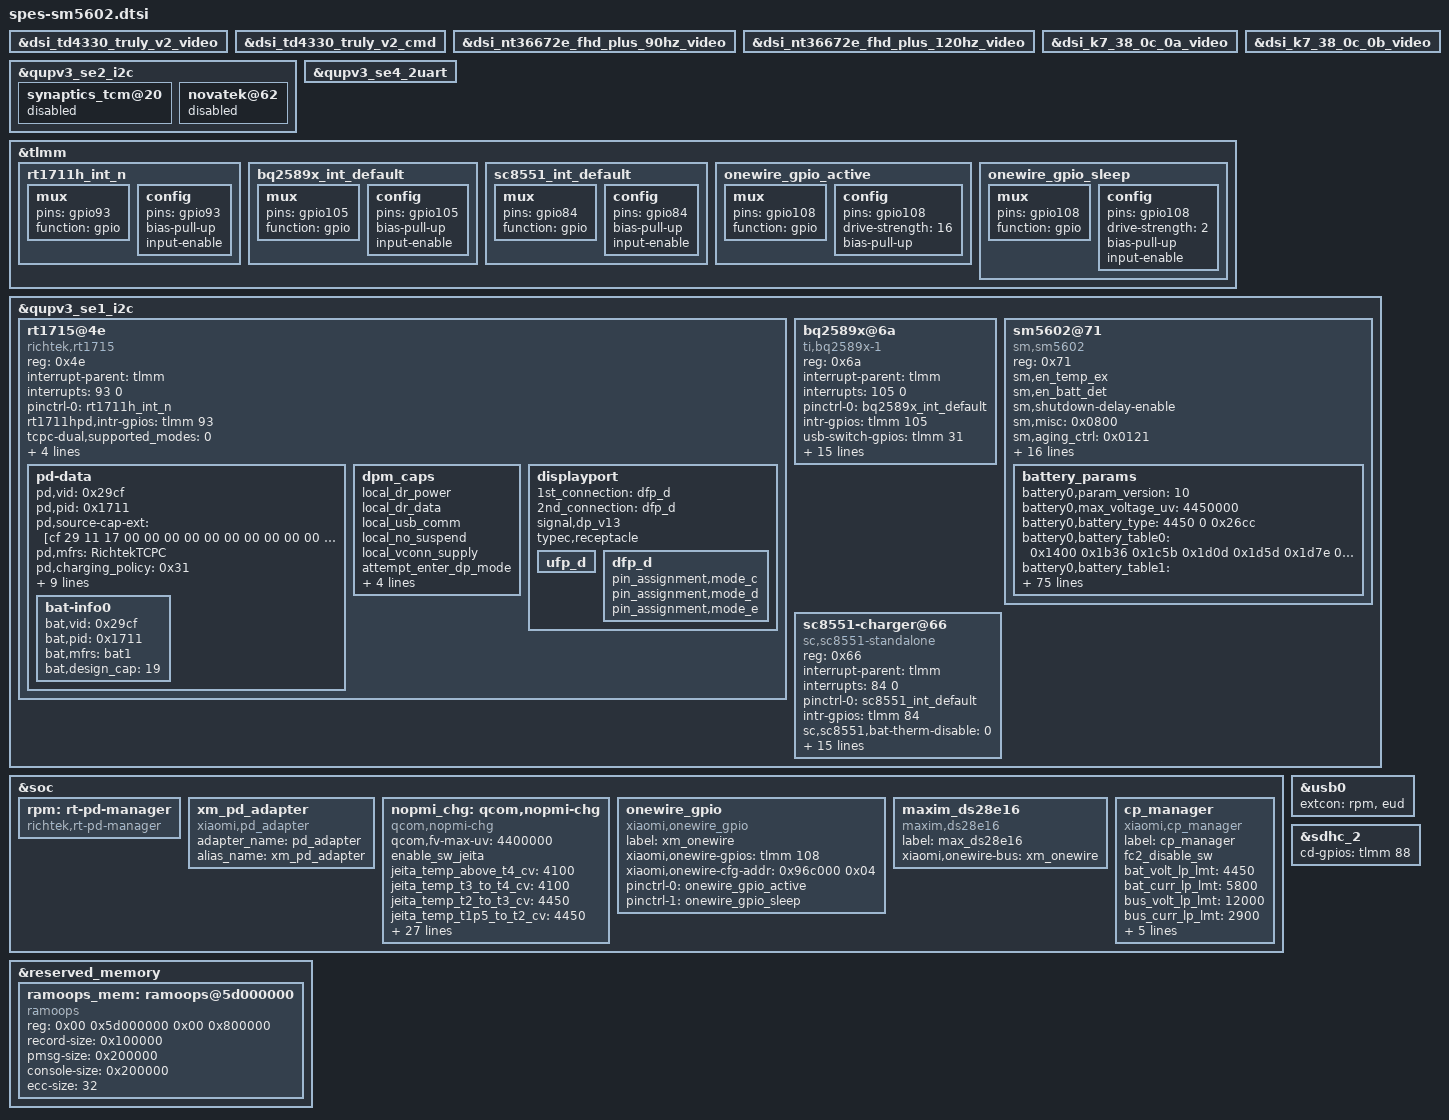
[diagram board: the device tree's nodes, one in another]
#include "khaje-idp.dtsi"

&dsi_td4330_truly_v2_video {
	/delete-property/ qcom,esd-check-enabled;
};

&dsi_td4330_truly_v2_cmd {
	/delete-property/ qcom,esd-check-enabled;
};

&dsi_nt36672e_fhd_plus_90hz_video {
	/delete-property/ qcom,esd-check-enabled;
};

&dsi_nt36672e_fhd_plus_120hz_video {
	/delete-property/ qcom,esd-check-enabled;
};

&dsi_k7_38_0c_0a_video {
	/delete-property/ qcom,esd-check-enabled;
};

&dsi_k7_38_0c_0b_video {
	/delete-property/ qcom,esd-check-enabled;
};

&qupv3_se2_i2c {
	synaptics_tcm@20 {
		status = "disabled";
	};

	novatek@62 {
		status = "disabled";
	};
};

&qupv3_se4_2uart {
	status = "ok";
};

&tlmm {
	/* RT1711H - TCPC */
	rt1711h_int_n: rt1711h_int_n {
		mux {
			pins = "gpio93";
			function = "gpio";
		};

		config {
			pins = "gpio93";
			bias-pull-up;
			input-enable;
		};
	};

	/* BQ-CHARGER */
	bq2589x_int_default: bq2589x_int_default {
		mux {
			pins = "gpio105";
			function = "gpio";
		};

		config {
			pins = "gpio105";
			bias-pull-up;
			input-enable;
		};
	};

	/* sc8551-charger */
	sc8551_int_default: sc8551_int_default {
		mux {
			pins = "gpio84";
			function = "gpio";
		};

		config {
			pins = "gpio84";
			bias-pull-up;
			input-enable;
		};
	};

	/* Onewire */
	onewire_gpio_active: onewire_gpio_active {
		mux {
			pins = "gpio108";
			function = "gpio";
		};

		config {
			pins = "gpio108";
			drive-strength = <16>;
			bias-pull-up;
		};
	};

	onewire_gpio_sleep: onewire_gpio_sleep {
		mux {
			pins = "gpio108";
			function = "gpio";
		};

		config {
			pins = "gpio108";
			drive-strength = <2>;
			bias-pull-up;
			input-enable;
		};
	};
};

&qupv3_se1_i2c {
	status = "ok";
	#address-cells = <1>;
	#size-cells = <0>;

	/* TCPC: Richtek RT1715 Type-C PD Controller */
	rt1715@4e {
		compatible = "richtek,rt1715";
		reg = <0x4e>;
		interrupt-parent = <&tlmm>;
		interrupts = <93 0>;
		pinctrl-names = "default";
		pinctrl-0 = <&rt1711h_int_n>;
		rt1711hpd,intr-gpios = <&tlmm 93 0>;
		tcpc-dual,supported_modes = <0>;
		rt-tcpc,name = "type_c_port0";
		/* 0: Unknown, 1: SNK, 2: SRC, 3: DRP, 4: Try.SRC, 5: Try.SNK */
		rt-tcpc,role_def = <5>;
		/* 0: Default, 1: 1.5A, 2: 3.0A */
		rt-tcpc,rp_level = <0>;
		/* 0: Never, 1: Always, 2: EMarkOnly, 3: StartOnly */
		rt-tcpc,vconn_supply = <1>;

		pd-data {
			pd,vid = <0x29cf>;
			pd,pid = <0x1711>;
			pd,source-cap-ext = [cf 29 11 17 00 00 00 00 00 00 00 00 00 00 00 00 00 00 00 00 00 00 00 02 00];
			pd,mfrs = "RichtekTCPC";
			/*
			 * VSAFE5V = 0x00, MAX_POWER = 0x01, CUSTOM = 0x02
			 * MAX_POWER_LV = 0x21, MAX_POWER_LVIC = 0x31
			 * MAX_POWER_HV = 0x41, MAX_POWER_HVIC = 0x51
			 */
			pd,charging_policy = <0x31>;

			/*
			 * Fixed 5V, 500 mA = <0x00019032>
			 * Fixed 5V, 1A = <0x00019064>
			 * Fixed 5V, 1.5A = <0x00019096>
			 * Fixed 5V, 2A = <0x000190c8>
			 * Fixed 5V, 3A = <0x0001912c>
			 * Fixed 9V, 500 mA = <0x0002d032>
			 * Fixed 9V, 1A = <0x0002d064>
			 * Fixed 9V, 2A = <0x0002d0c8>
			 * Fixed 9V, 3A = <0x0002d12c>
			 * Variable 5-9V, 1A = <0x8642d064>
			 * Variable 5-9V, 2A = <0x8642d0c8>
			 * Variable 5-9V, 3A = <0x8642d12c>
			 * PPS 3V ~ 5.9V, 3A = <0xC0761E3C>
			 * PPS 5V ~ 11.0V, 3A = <0xC0DC323C>
			 */
			pd,source-pdo-size = <1>;
			pd,source-pdo-data = <0x00019032>;
			pd,sink-pdo-size = <1>;
			pd,sink-pdo-data = <0x000190c8>;
			pd,id-vdo-size = <6>;
			pd,id-vdo-data = <0xd14029cf 0x0 0x17110000 0x61000000 0x0 0x41000000>;
			bat,nr = <1>;
			pd,country_nr = <0>;
			bat-info0 {
				bat,vid = <0x29cf>;
				bat,pid = <0x1711>;
				bat,mfrs = "bat1";
				bat,design_cap = <19>;
			};
		};

		dpm_caps {
			local_dr_power;
			local_dr_data;
			local_usb_comm;
			local_no_suspend;
			local_vconn_supply;
			attempt_enter_dp_mode;
			attempt_discover_cable;
			attempt_discover_id;
			pr_check = <0>;
			dr_check = <0>;
		};

		displayport {
			1st_connection = "dfp_d";
			2nd_connection = "dfp_d";
			signal,dp_v13;
			typec,receptacle;

			ufp_d {};

			dfp_d {
				pin_assignment,mode_c;
				pin_assignment,mode_d;
				pin_assignment,mode_e;
			};
		};
	};

	/* BQ charger */
	bq2589x@6a {
		compatible = "ti,bq2589x-1";
		reg = <0x6a>;
		interrupt-parent = <&tlmm>;
		interrupts = <105 0>;
		pinctrl-names = "default";
		pinctrl-0 = <&bq2589x_int_default>;
		intr-gpios = <&tlmm 105 0>;
		usb-switch-gpios = <&tlmm 31 0>;
		ti,bq2589x,vbus-volt-high-level = <8700>;
		ti,bq2589x,vbus-volt-low-level = <4400>;
		ti,bq2589x,vbat-min-volt-to-tuneup = <3000>;
		ti,bq2589x,charge-voltage = <4450>;
		ti,bq2589x,charge-current = <2000>;
		ti,bq2589x,charge-current-1500 = <1500>;
		ti,bq2589x,charge-current-1000 = <1000>;
		ti,bq2589x,charge-current-500 = <500>;
		ti,bq2589x,charge-current-3500 = <3500>;
		ti,bq2589x,input-current-2000 = <2000>;
		ti,bq2589x,term-current = <256>;
		ti,bq2589x,enable-auto-dpdm;
		ti,bq2589x,enable-termination;
		ti,bq2589x,enable-ico;
		ti,bq2589x,use-absolute-vindpm;
	};

	/* Fuel gauge */
	sm5602@71 {
		compatible = "sm,sm5602";
		reg = <0x71>;
		sm,en_temp_ex;
		sm,en_batt_det;
		sm,shutdown-delay-enable;
		sm,misc = <0x0800>;
		sm,aging_ctrl = <0x0121>;
		sm,cycle_cfg = <0x7000>;
		sm,fg_irq_set = <0x07ff>;
		sm,rsns = <0>;
		sm,battery_table_num = <0>;
		sm,param_version = <5>;
		sm,low_soc1 = <1>;
		sm,low_soc2 = <15>;
		sm,v_l_alarm = <3400>;
		sm,v_h_alarm = <4450>;
		sm,t_l_alarm_in = <54>;
		sm,t_h_alarm_in = <1>;
		sm,t_l_alarm_ex = <0xd632>;
		sm,t_h_alarm_ex = <0x955f>;
		sm,rtrace = <7300>;
		sm,soc_decimal_rate = <0 38 10 35 20 33 30 33 40 33 50 33 60 33 70 30 80 25 90 20 95 10>;

		battery_params {
			/* battery 0 */
			battery0,param_version = <10>;
			battery0,max_voltage_uv = <4450000>;
			battery0,battery_type = <4450 0 0x26cc>;
			battery0,battery_table0 = <0x1400 0x1b36 0x1c5b 0x1d0d 0x1d5d 0x1d7e 0x1d8d 0x1d97 0x1dc1 0x1df0 0x1e1a 0x1e4a 0x1e6a 0x1ea2 0x1eee 0x1f37 0x1fb9 0x2015 0x2079 0x20e8 0x219c 0x2257 0x2351 0x24cc>;
			battery0,battery_table1 = <0x00 0x66 0x1ea 0x36f 0x472 0x574 0x7fc 0xb04 0xe0d 0x1218 0x1727 0x1c35 0x2143 0x28d9 0x306e 0x357c 0x3a8b 0x3f99 0x44a7 0x49b5 0x514b 0x58e0 0x6400 0x64e6>;
			battery0,battery_table2 = <0x1620 0x1113 0xf10 0xd0e 0xc0c 0xb0b 0xa0a 0xa0a>;
			battery0,alpha = <0xcc>;
			battery0,beta = <0x25>;
			battery0,rs = <0x5f>;
			battery0,rs_value = <0x50 0x10a 0x3800 0x48>;
			battery0,vit_period = <0x325a>;
			battery0,volt_cal = <0x8000>;
			battery0,mix_value = <3>;
			battery0,curr_offset = <0x00>;
			battery0,curr_slope = <0x8080>;
			battery0,topoff_soc = <7 300 100>;
			battery0,temp_std = <25>;
			battery0,temp_offset = <0 11 1 0 8 (-1)>;
			battery0,temp_cal = <0 6 1 11 (-1) 0 6 1 9 1>;
			battery0,ext_temp_cal = <0 2 1 2 1 1 2 3 2 3>;
			battery0,tempoff = <3400 100>;
			battery0,fcm_offset = <0x48>;
			battery0,thermal_table = <0x9d45 0x9cf7 0x9ca8 0x9c5a 0x9c0c 0x9bbe 0x9b70 0x9b21 0x9ad2 0x9a83 0x9a33 0x99e3 0x9992 0x9940 0x98ef 0x989d 0x984b 0x97f8 0x97a5 0x9752
				0x96fe 0x96aa 0x9656 0x9601 0x95ac 0x9556 0x9500 0x94aa 0x9454 0x93fd 0x93a6 0x934f 0x92f7 0x929f 0x9246 0x91ed 0x9194 0x913b 0x90e1 0x9087
				0x902d 0x8fd2 0x8f78 0x8f1c 0x8ec1 0x8e65 0x8e09 0x8dad 0x8d51 0x8cf4 0x8c97 0x8c3a 0x8bdd 0x8b7f 0x8b21 0x8ac3 0x8a65 0x8a06 0x89a8 0x8949
				0x88ea 0x888b 0x882c 0x87cc 0x876d 0x870d 0x86ad 0x864d 0x85ed 0x858d 0x852d 0x84d1 0x847c 0x842b 0x83db 0x8389 0x8332 0x82d3 0x8269 0x81f1
				0x8168 0x80aa 0x7fa2 0x7e62 0x7cfd 0x7b85 0x7a0e 0x78a9 0x7769 0x7662 0x75a5 0x751d 0x74a6 0x743d 0x73df 0x7388 0x7337 0x72e8 0x7297 0x7244
				0x71e9 0x718a 0x712b 0x70cd 0x706e 0x7010 0x6fb2 0x6f54 0x6ef6 0x6e98 0x6e3b 0x6dde 0x6d81 0x6d24 0x6cc7 0x6c6b 0x6c0e 0x6bb2 0x6b57 0x6afb
				0x6aa0 0x6a45 0x69ea 0x6990 0x6936 0x68dc 0x6882 0x6829 0x67cf 0x6777 0x671e 0x66c6 0x666e 0x6616 0x65bf 0x6567 0x6510 0x64ba 0x6464 0x640e
				0x63b8 0x6363 0x630e 0x62b9 0x6265 0x6211 0x61bd 0x6169 0x6116 0x60c3 0x6071 0x601f 0x5fcd 0x5f7b 0x5f2a 0x5ed9 0x5e89 0x5e39 0x5de9 0x5d99
				0x5d4a 0x5cfb 0x5cad 0x5c5f 0x5c11 0x5bc4 0x5b76 0x5b2a 0x5add 0x5a91 0x5a45 0x59f9 0x59ae 0x5963 0x5918 0x58ce 0x5884 0x583a 0x57f0 0x57a7
				0x575e 0x5715 0x56cd 0x5685 0x563d 0x55f6 0x55af 0x5568 0x5522 0x54db 0x5495 0x544f 0x540a 0x53c4 0x537f 0x533a 0x52f6 0x52b1 0x526d 0x5229
				0x51e5 0x51a1 0x515e 0x511a 0x50d7 0x5094 0x5052 0x500f 0x4fcc 0x4f8a 0x4f48 0x4f06 0x4ec4 0x4e83 0x4e41 0x4e00 0x4dbf 0x4d7e 0x4d3d 0x4cfc
				0x4cbb 0x4c7a 0x4c3a 0x4bf9 0x4bb8 0x4b78 0x4b38 0x4af7 0x4ab7 0x4a77 0x4a37 0x49f7 0x49b7 0x4977 0x4937 0x48f8 0x48b8 0x4879 0x4839 0x47f9
				0x47ba 0x477b 0x473b 0x46fc 0x46bd 0x467d 0x463e 0x45ff 0x45c0 0x4581 0x4542 0x4503 0x44c4 0x4485 0x4447 0x4408 0x43c9 0x438b 0x434c 0x430e
				0x42d0 0x4292 0x4254 0x4216 0x41d8 0x419a 0x415d 0x4120 0x40e2 0x40a6 0x4069 0x402d 0x3ff0 0x3fb4 0x3f79 0x3f3d 0x3f02 0x3ec6 0x3e8c 0x3e51
				0x3e17 0x3ddd 0x3da4 0x3d6a 0x3d31 0x3cf9 0x3cc0 0x3c88 0x3c50 0x3c18 0x3be1 0x3baa 0x3b73 0x3b3d 0x3b06 0x3ad1 0x3a9b 0x3a65 0x3a30 0x39fb
				0x39c6 0x3991 0x395d 0x3928 0x38f4 0x38c0 0x388c 0x3859 0x3826 0x37f3 0x37c0 0x378e 0x375b 0x3729 0x36f8 0x36c6 0x3695 0x3664 0x3634 0x3603
				0x35d3 0x35a3 0x3574 0x3544 0x3515 0x34e7 0x34b8 0x348a 0x345c 0x342e 0x3400 0x33d3 0x33a5 0x3378 0x334b 0x331f 0x32f2 0x32c6 0x329a 0x326e
				0x3242 0x3216 0x31ea 0x31bf 0x3193 0x3167 0x313c 0x3111 0x30e6 0x30bc 0x3092 0x3068 0x303f 0x3016 0x2fed 0x2fc5 0x2f9c 0x2f74 0x2f4c 0x2f25
				0x2efd 0x2ed6 0x2eaf 0x2e88 0x2e61 0x2e3b 0x2e14 0x2dee 0x2dc8 0x2da2 0x2d7c 0x2d56 0x2d30 0x2d0a 0x2ce5 0x2cbf 0x2c99 0x2c74 0x2c4f 0x2c2a
				0x2c06 0x2be2 0x2bbe 0x2b9a 0x2b77 0x2b54 0x2b31 0x2b0e 0x2aeb 0x2ac9 0x2aa6 0x2a83 0x2a61 0x2a3f 0x2a1c 0x29fa 0x29d9 0x29b7 0x2995 0x2974
				0x2953 0x2932 0x2912 0x28f2 0x28d2 0x28b2 0x2892 0x2872 0x2853 0x2833 0x2814 0x27f5 0x27d5 0x27b6 0x2796 0x2777 0x2758 0x2739 0x271a 0x26fc
				0x26de 0x26c0 0x26a3 0x2686 0x2669 0x264c 0x2630 0x2613 0x25f7 0x25da 0x25be 0x25a2 0x2585 0x2569 0x254c 0x2530 0x2514 0x24f8 0x24dc 0x24c0
				0x24a5 0x248a 0x246f 0x2454 0x2439 0x241f 0x2404 0x23ea 0x23d0 0x23b6 0x239c 0x2382 0x2369 0x234f 0x2336 0x231d 0x2304 0x22eb 0x22d2 0x22ba
				0x22a1 0x2289 0x2270 0x2258 0x2240 0x2228 0x2210 0x21f8 0x21e0 0x21c9 0x21b1 0x219a 0x2182 0x216b 0x2154 0x213c 0x2125 0x210f 0x20f8 0x20e1
				0x20cb 0x20b5 0x209f 0x2089 0x2073 0x205e 0x2048 0x2033 0x201d 0x2008 0x1ff3 0x1fde 0x1fc9 0x1fb4 0x1f9f 0x1f8a 0x1f75 0x1f61 0x1f4c 0x1f38
				0x1f23 0x1f0f 0x1efa 0x1ee6 0x1ed1 0x1ebd 0x1ea9 0x1e95 0x1e81 0x1e6d 0x1e59 0x1e45 0x1e32 0x1e1f 0x1e0b 0x1df8 0x1de5 0x1dd2 0x1dbf 0x1dad
				0x1d9a 0x1d88 0x1d75 0x1d63 0x1d51 0x1d3f 0x1d2e 0x1d1c 0x1d0a 0x1cf9 0x1ce7 0x1cd5 0x1cc4 0x1cb3 0x1ca1 0x1c90 0x1c7f 0x1c6e 0x1c5d 0x1c4c
				0x1c3b 0x1c2a 0x1c19 0x1c09 0x1bf8 0x1be7 0x1bd7 0x1bc6 0x1bb6 0x1ba5 0x1b95 0x1b85 0x1b75 0x1b65 0x1b55 0x1b45 0x1b35 0x1b25 0x1b16 0x1b06
				0x1af7 0x1ae8 0x1ad9 0x1ac9 0x1abb 0x1aac 0x1a9d 0x1a8e 0x1a7f 0x1a71 0x1a62 0x1a53 0x1a45 0x1a36 0x1a28 0x1a19 0x1a0b 0x19fc 0x19ee 0x19e0
				0x19d2 0x19c4 0x19b6 0x19a9 0x199b 0x198e 0x1980 0x1973 0x1965 0x1958 0x194b 0x193e 0x1931 0x1924 0x1917 0x190a 0x18fe 0x18f1 0x18e4 0x18d8
				0x18cb 0x18be 0x18b2 0x18a5 0x1899 0x188c 0x187f 0x1873 0x1867 0x185a 0x184e 0x1842 0x1836 0x1829 0x181d 0x1811 0x1805 0x17f9 0x17ed 0x17e2
				0x17d6 0x17ca 0x17bf 0x17b3 0x17a8 0x179d 0x1791 0x1786 0x177b 0x1770 0x1765 0x175a 0x174f 0x1744 0x173a 0x172f 0x1724 0x171a 0x170f 0x1705
				0x16fa 0x16f0 0x16e5 0x16db 0x16d0 0x16c6 0x16bc 0x16b1 0x16a7 0x169d 0x1693 0x1689 0x167f 0x1675 0x166b 0x1661 0x1658 0x164e 0x1644 0x163b
				0x1631 0x1627 0x161e 0x1614 0x160b 0x1601 0x15f8 0x15ef 0x15e5 0x15dc 0x15d3 0x15ca 0x15c1 0x15b8 0x15af 0x15a5 0x159d 0x1594 0x158b 0x1582
				0x1579 0x1570 0x1568 0x155f 0x1556 0x154e 0x1545 0x153d 0x1534 0x152c 0x1523 0x151a 0x1512 0x1509 0x1501 0x14f8 0x14f0 0x14e8 0x14df 0x14d7
				0x14cf 0x14c7 0x14bf 0x14b7 0x14af 0x14a8 0x14a0 0x1498 0x1490 0x1489 0x1481 0x1479 0x1472 0x146a 0x1462 0x145b 0x1453 0x144c 0x1444 0x143c
				0x1435 0x142e 0x1426 0x141f 0x1417 0x1410 0x1409 0x1402 0x13fa 0x13f3 0x13ec 0x13e5 0x13de 0x13d7 0x13d0 0x13c9 0x13c2 0x13bb 0x13b4 0x13ad
				0x13a6 0x139f 0x1399 0x1392 0x138b 0x1385 0x137e 0x1377 0x1371 0x136a 0x1364 0x135e 0x1357 0x1351 0x134a 0x1344 0x133e 0x1338 0x1331 0x132b
				0x1325 0x131f 0x1319 0x1313 0x130d 0x1307 0x1301 0x12fb 0x12f6 0x12f0 0x12ea 0x12e4 0x12de 0x12d9 0x12d3 0x12cd 0x12c7 0x12c2 0x12bc 0x12b7
				0x12b1 0x12ab 0x12a6 0x12a1 0x129b 0x1296 0x1290 0x128b 0x1286 0x1280 0x127b 0x1276 0x1270 0x126b 0x1265 0x1260 0x125a 0x1255 0x1250 0x124a
				0x1245 0x1240 0x123b 0x1235 0x1230 0x122b 0x1226 0x1221 0x121c 0x1217 0x1212 0x120d 0x1208 0x1203 0x11fe 0x11f9 0x11f4 0x11ef 0x11eb 0x11e6
				0x11e1 0x11dc 0x11d7 0x11d3 0x11ce 0x11c9 0x11c5 0x11c0 0x11bb 0x11b7 0x11b2 0x11ad 0x11a9 0x11a4 0x11a0 0x119b 0x1197 0x1192 0x118e 0x1189
				0x1185 0x1181 0x117c 0x1178 0x1174 0x116f 0x116b 0x1167 0x1162 0x115e 0x115a 0x1156 0x1152 0x114e 0x114a 0x1146 0x1142 0x113e 0x113a 0x1136
				0x1132 0x112e 0x112a 0x1126 0x1122 0x111e 0x111a 0x1117 0x1113 0x110f 0x110b 0x1107 0x1103 0x1100 0x10fc 0x10f8 0x10f5 0x10f1 0x10ed 0x10ea
				0x10e6 0x10e2 0x10df 0x10db 0x10d7 0x10d4 0x10d0 0x10cd 0x10c9 0x10c6 0x10c2 0x10bf 0x10bb 0x10b8 0x10b4 0x10b1 0x10ae 0x10aa 0x10a7 0x10a3
				0x10a0 0x109d 0x1099 0x1096 0x1092 0x108f 0x108b 0x1088 0x1085 0x1081 0x107e 0x107b 0x1077 0x1074 0x1071 0x106e 0x106b 0x1067 0x1064 0x1061
				0x105e 0x105b 0x1058 0x1055 0x1052 0x104f 0x104c 0x1049 0x1046 0x1043 0x1040 0x103d 0x103a 0x1037 0x1034 0x1031 0x102e 0x102b 0x1028 0x1025
				0x1022 0x101f 0x101c 0x1019 0x1017 0x1014 0x1011 0x100e 0x100c 0x1009 0x1006 0x1003 0x1000 0x0ffe 0x0ffb 0x0ff8 0x0ff5 0x0ff2 0x0fef 0x0fed
				0x0fea 0x0fe7 0x0fe5 0x0fe2 0x0fdf 0x0fdd 0x0fda 0x0fd8 0x0fd5 0x0fd3 0x0fd0 0x0fcd 0x0fcb 0x0fc8 0x0fc6 0x0fc3 0x0fc1 0x0fbe 0x0fbc 0x0fb9
				0x0fb7 0x0fb5 0x0fb2 0x0fb0 0x0fae 0x0fab 0x0fa9 0x0fa7 0x0fa5 0x0fa2 0x0fa0 0x0f9e 0x0f9c 0x0f99 0x0f97 0x0f95 0x0f93 0x0f91 0x0f8e 0x0f8c 0x0f8a>;
			/* battery 1 */
			battery1,param_version = <10>;
			battery1,max_voltage_uv = <4450000>;
			battery1,battery_type = <4450 0 0x26cc>;
			battery1,battery_table0 = <0x1400 0x1b36 0x1c5b 0x1d0d 0x1d5d 0x1d7e 0x1d8d 0x1d97 0x1dc1 0x1df0 0x1e1a 0x1e4a 0x1e6a 0x1ea2 0x1eee 0x1f37 0x1fb9 0x2015 0x2079 0x20e8 0x219c 0x2257 0x2351 0x24cc>;
			battery1,battery_table1 = <0x00 0x66 0x1ea 0x36f 0x472 0x574 0x7fc 0xb04 0xe0d 0x1218 0x1727 0x1c35 0x2143 0x28d9 0x306e 0x357c 0x3a8b 0x3f99 0x44a7 0x49b5 0x514b 0x58e0 0x6400 0x64e6>;
			battery1,battery_table2 = <0x1620 0x1113 0xf10 0xd0e 0xc0c 0xb0b 0xa0a 0xa0a>;
			battery1,alpha = <0xcc>;
			battery1,beta = <0x25>;
			battery1,rs = <0x5f>;
			battery1,rs_value = <0x50 0x10a 0x3800 0x48>;
			battery1,vit_period = <0x325a>;
			battery1,volt_cal = <0x8000>;
			battery1,mix_value = <3>;
			battery1,curr_offset = <0x00>;
			battery1,curr_slope = <0x8080>;
			battery1,topoff_soc = <7 300 100>;
			battery1,temp_std = <25>;
			battery1,temp_offset = <0 11 1 0 8 (-1)>;
			battery1,temp_cal = <0 6 1 11 (-1) 0 6 1 9 1>;
			battery1,ext_temp_cal = <0 2 1 2 1 1 2 3 2 3>;
			battery1,tempoff = <3400 100>;
			battery1,fcm_offset = <0x48>;
			battery1,thermal_table = <0x9d45 0x9cf7 0x9ca8 0x9c5a 0x9c0c 0x9bbe 0x9b70 0x9b21 0x9ad2 0x9a83 0x9a33 0x99e3 0x9992 0x9940 0x98ef 0x989d 0x984b 0x97f8 0x97a5 0x9752
				0x96fe 0x96aa 0x9656 0x9601 0x95ac 0x9556 0x9500 0x94aa 0x9454 0x93fd 0x93a6 0x934f 0x92f7 0x929f 0x9246 0x91ed 0x9194 0x913b 0x90e1 0x9087
				0x902d 0x8fd2 0x8f78 0x8f1c 0x8ec1 0x8e65 0x8e09 0x8dad 0x8d51 0x8cf4 0x8c97 0x8c3a 0x8bdd 0x8b7f 0x8b21 0x8ac3 0x8a65 0x8a06 0x89a8 0x8949
				0x88ea 0x888b 0x882c 0x87cc 0x876d 0x870d 0x86ad 0x864d 0x85ed 0x858d 0x852d 0x84d1 0x847c 0x842b 0x83db 0x8389 0x8332 0x82d3 0x8269 0x81f1
				0x8168 0x80aa 0x7fa2 0x7e62 0x7cfd 0x7b85 0x7a0e 0x78a9 0x7769 0x7662 0x75a5 0x751d 0x74a6 0x743d 0x73df 0x7388 0x7337 0x72e8 0x7297 0x7244
				0x71e9 0x718a 0x712b 0x70cd 0x706e 0x7010 0x6fb2 0x6f54 0x6ef6 0x6e98 0x6e3b 0x6dde 0x6d81 0x6d24 0x6cc7 0x6c6b 0x6c0e 0x6bb2 0x6b57 0x6afb
				0x6aa0 0x6a45 0x69ea 0x6990 0x6936 0x68dc 0x6882 0x6829 0x67cf 0x6777 0x671e 0x66c6 0x666e 0x6616 0x65bf 0x6567 0x6510 0x64ba 0x6464 0x640e
				0x63b8 0x6363 0x630e 0x62b9 0x6265 0x6211 0x61bd 0x6169 0x6116 0x60c3 0x6071 0x601f 0x5fcd 0x5f7b 0x5f2a 0x5ed9 0x5e89 0x5e39 0x5de9 0x5d99
				0x5d4a 0x5cfb 0x5cad 0x5c5f 0x5c11 0x5bc4 0x5b76 0x5b2a 0x5add 0x5a91 0x5a45 0x59f9 0x59ae 0x5963 0x5918 0x58ce 0x5884 0x583a 0x57f0 0x57a7
				0x575e 0x5715 0x56cd 0x5685 0x563d 0x55f6 0x55af 0x5568 0x5522 0x54db 0x5495 0x544f 0x540a 0x53c4 0x537f 0x533a 0x52f6 0x52b1 0x526d 0x5229
				0x51e5 0x51a1 0x515e 0x511a 0x50d7 0x5094 0x5052 0x500f 0x4fcc 0x4f8a 0x4f48 0x4f06 0x4ec4 0x4e83 0x4e41 0x4e00 0x4dbf 0x4d7e 0x4d3d 0x4cfc
				0x4cbb 0x4c7a 0x4c3a 0x4bf9 0x4bb8 0x4b78 0x4b38 0x4af7 0x4ab7 0x4a77 0x4a37 0x49f7 0x49b7 0x4977 0x4937 0x48f8 0x48b8 0x4879 0x4839 0x47f9
				0x47ba 0x477b 0x473b 0x46fc 0x46bd 0x467d 0x463e 0x45ff 0x45c0 0x4581 0x4542 0x4503 0x44c4 0x4485 0x4447 0x4408 0x43c9 0x438b 0x434c 0x430e
				0x42d0 0x4292 0x4254 0x4216 0x41d8 0x419a 0x415d 0x4120 0x40e2 0x40a6 0x4069 0x402d 0x3ff0 0x3fb4 0x3f79 0x3f3d 0x3f02 0x3ec6 0x3e8c 0x3e51
				0x3e17 0x3ddd 0x3da4 0x3d6a 0x3d31 0x3cf9 0x3cc0 0x3c88 0x3c50 0x3c18 0x3be1 0x3baa 0x3b73 0x3b3d 0x3b06 0x3ad1 0x3a9b 0x3a65 0x3a30 0x39fb
				0x39c6 0x3991 0x395d 0x3928 0x38f4 0x38c0 0x388c 0x3859 0x3826 0x37f3 0x37c0 0x378e 0x375b 0x3729 0x36f8 0x36c6 0x3695 0x3664 0x3634 0x3603
				0x35d3 0x35a3 0x3574 0x3544 0x3515 0x34e7 0x34b8 0x348a 0x345c 0x342e 0x3400 0x33d3 0x33a5 0x3378 0x334b 0x331f 0x32f2 0x32c6 0x329a 0x326e
				0x3242 0x3216 0x31ea 0x31bf 0x3193 0x3167 0x313c 0x3111 0x30e6 0x30bc 0x3092 0x3068 0x303f 0x3016 0x2fed 0x2fc5 0x2f9c 0x2f74 0x2f4c 0x2f25
				0x2efd 0x2ed6 0x2eaf 0x2e88 0x2e61 0x2e3b 0x2e14 0x2dee 0x2dc8 0x2da2 0x2d7c 0x2d56 0x2d30 0x2d0a 0x2ce5 0x2cbf 0x2c99 0x2c74 0x2c4f 0x2c2a
				0x2c06 0x2be2 0x2bbe 0x2b9a 0x2b77 0x2b54 0x2b31 0x2b0e 0x2aeb 0x2ac9 0x2aa6 0x2a83 0x2a61 0x2a3f 0x2a1c 0x29fa 0x29d9 0x29b7 0x2995 0x2974
				0x2953 0x2932 0x2912 0x28f2 0x28d2 0x28b2 0x2892 0x2872 0x2853 0x2833 0x2814 0x27f5 0x27d5 0x27b6 0x2796 0x2777 0x2758 0x2739 0x271a 0x26fc
				0x26de 0x26c0 0x26a3 0x2686 0x2669 0x264c 0x2630 0x2613 0x25f7 0x25da 0x25be 0x25a2 0x2585 0x2569 0x254c 0x2530 0x2514 0x24f8 0x24dc 0x24c0
				0x24a5 0x248a 0x246f 0x2454 0x2439 0x241f 0x2404 0x23ea 0x23d0 0x23b6 0x239c 0x2382 0x2369 0x234f 0x2336 0x231d 0x2304 0x22eb 0x22d2 0x22ba
				0x22a1 0x2289 0x2270 0x2258 0x2240 0x2228 0x2210 0x21f8 0x21e0 0x21c9 0x21b1 0x219a 0x2182 0x216b 0x2154 0x213c 0x2125 0x210f 0x20f8 0x20e1
				0x20cb 0x20b5 0x209f 0x2089 0x2073 0x205e 0x2048 0x2033 0x201d 0x2008 0x1ff3 0x1fde 0x1fc9 0x1fb4 0x1f9f 0x1f8a 0x1f75 0x1f61 0x1f4c 0x1f38
				0x1f23 0x1f0f 0x1efa 0x1ee6 0x1ed1 0x1ebd 0x1ea9 0x1e95 0x1e81 0x1e6d 0x1e59 0x1e45 0x1e32 0x1e1f 0x1e0b 0x1df8 0x1de5 0x1dd2 0x1dbf 0x1dad
				0x1d9a 0x1d88 0x1d75 0x1d63 0x1d51 0x1d3f 0x1d2e 0x1d1c 0x1d0a 0x1cf9 0x1ce7 0x1cd5 0x1cc4 0x1cb3 0x1ca1 0x1c90 0x1c7f 0x1c6e 0x1c5d 0x1c4c
				0x1c3b 0x1c2a 0x1c19 0x1c09 0x1bf8 0x1be7 0x1bd7 0x1bc6 0x1bb6 0x1ba5 0x1b95 0x1b85 0x1b75 0x1b65 0x1b55 0x1b45 0x1b35 0x1b25 0x1b16 0x1b06
				0x1af7 0x1ae8 0x1ad9 0x1ac9 0x1abb 0x1aac 0x1a9d 0x1a8e 0x1a7f 0x1a71 0x1a62 0x1a53 0x1a45 0x1a36 0x1a28 0x1a19 0x1a0b 0x19fc 0x19ee 0x19e0
				0x19d2 0x19c4 0x19b6 0x19a9 0x199b 0x198e 0x1980 0x1973 0x1965 0x1958 0x194b 0x193e 0x1931 0x1924 0x1917 0x190a 0x18fe 0x18f1 0x18e4 0x18d8
				0x18cb 0x18be 0x18b2 0x18a5 0x1899 0x188c 0x187f 0x1873 0x1867 0x185a 0x184e 0x1842 0x1836 0x1829 0x181d 0x1811 0x1805 0x17f9 0x17ed 0x17e2
				0x17d6 0x17ca 0x17bf 0x17b3 0x17a8 0x179d 0x1791 0x1786 0x177b 0x1770 0x1765 0x175a 0x174f 0x1744 0x173a 0x172f 0x1724 0x171a 0x170f 0x1705
				0x16fa 0x16f0 0x16e5 0x16db 0x16d0 0x16c6 0x16bc 0x16b1 0x16a7 0x169d 0x1693 0x1689 0x167f 0x1675 0x166b 0x1661 0x1658 0x164e 0x1644 0x163b
				0x1631 0x1627 0x161e 0x1614 0x160b 0x1601 0x15f8 0x15ef 0x15e5 0x15dc 0x15d3 0x15ca 0x15c1 0x15b8 0x15af 0x15a5 0x159d 0x1594 0x158b 0x1582
				0x1579 0x1570 0x1568 0x155f 0x1556 0x154e 0x1545 0x153d 0x1534 0x152c 0x1523 0x151a 0x1512 0x1509 0x1501 0x14f8 0x14f0 0x14e8 0x14df 0x14d7
				0x14cf 0x14c7 0x14bf 0x14b7 0x14af 0x14a8 0x14a0 0x1498 0x1490 0x1489 0x1481 0x1479 0x1472 0x146a 0x1462 0x145b 0x1453 0x144c 0x1444 0x143c
				0x1435 0x142e 0x1426 0x141f 0x1417 0x1410 0x1409 0x1402 0x13fa 0x13f3 0x13ec 0x13e5 0x13de 0x13d7 0x13d0 0x13c9 0x13c2 0x13bb 0x13b4 0x13ad
				0x13a6 0x139f 0x1399 0x1392 0x138b 0x1385 0x137e 0x1377 0x1371 0x136a 0x1364 0x135e 0x1357 0x1351 0x134a 0x1344 0x133e 0x1338 0x1331 0x132b
				0x1325 0x131f 0x1319 0x1313 0x130d 0x1307 0x1301 0x12fb 0x12f6 0x12f0 0x12ea 0x12e4 0x12de 0x12d9 0x12d3 0x12cd 0x12c7 0x12c2 0x12bc 0x12b7
				0x12b1 0x12ab 0x12a6 0x12a1 0x129b 0x1296 0x1290 0x128b 0x1286 0x1280 0x127b 0x1276 0x1270 0x126b 0x1265 0x1260 0x125a 0x1255 0x1250 0x124a
				0x1245 0x1240 0x123b 0x1235 0x1230 0x122b 0x1226 0x1221 0x121c 0x1217 0x1212 0x120d 0x1208 0x1203 0x11fe 0x11f9 0x11f4 0x11ef 0x11eb 0x11e6
				0x11e1 0x11dc 0x11d7 0x11d3 0x11ce 0x11c9 0x11c5 0x11c0 0x11bb 0x11b7 0x11b2 0x11ad 0x11a9 0x11a4 0x11a0 0x119b 0x1197 0x1192 0x118e 0x1189
				0x1185 0x1181 0x117c 0x1178 0x1174 0x116f 0x116b 0x1167 0x1162 0x115e 0x115a 0x1156 0x1152 0x114e 0x114a 0x1146 0x1142 0x113e 0x113a 0x1136
				0x1132 0x112e 0x112a 0x1126 0x1122 0x111e 0x111a 0x1117 0x1113 0x110f 0x110b 0x1107 0x1103 0x1100 0x10fc 0x10f8 0x10f5 0x10f1 0x10ed 0x10ea
				0x10e6 0x10e2 0x10df 0x10db 0x10d7 0x10d4 0x10d0 0x10cd 0x10c9 0x10c6 0x10c2 0x10bf 0x10bb 0x10b8 0x10b4 0x10b1 0x10ae 0x10aa 0x10a7 0x10a3
				0x10a0 0x109d 0x1099 0x1096 0x1092 0x108f 0x108b 0x1088 0x1085 0x1081 0x107e 0x107b 0x1077 0x1074 0x1071 0x106e 0x106b 0x1067 0x1064 0x1061
				0x105e 0x105b 0x1058 0x1055 0x1052 0x104f 0x104c 0x1049 0x1046 0x1043 0x1040 0x103d 0x103a 0x1037 0x1034 0x1031 0x102e 0x102b 0x1028 0x1025
				0x1022 0x101f 0x101c 0x1019 0x1017 0x1014 0x1011 0x100e 0x100c 0x1009 0x1006 0x1003 0x1000 0x0ffe 0x0ffb 0x0ff8 0x0ff5 0x0ff2 0x0fef 0x0fed
				0x0fea 0x0fe7 0x0fe5 0x0fe2 0x0fdf 0x0fdd 0x0fda 0x0fd8 0x0fd5 0x0fd3 0x0fd0 0x0fcd 0x0fcb 0x0fc8 0x0fc6 0x0fc3 0x0fc1 0x0fbe 0x0fbc 0x0fb9
				0x0fb7 0x0fb5 0x0fb2 0x0fb0 0x0fae 0x0fab 0x0fa9 0x0fa7 0x0fa5 0x0fa2 0x0fa0 0x0f9e 0x0f9c 0x0f99 0x0f97 0x0f95 0x0f93 0x0f91 0x0f8e 0x0f8c 0x0f8a>;
			/* battery 2 */
			battery2,param_version = <10>;
			battery2,max_voltage_uv = <4450000>;
			battery2,battery_type = <4450 0 0x2699>;
			battery2,battery_table0 = <0x1400 0x1b48 0x1c6f 0x1cee 0x1d4a 0x1d7d 0x1d8d 0x1d9b 0x1dcd 0x1e03 0x1e2e 0x1e5c 0x1e7b 0x1e9f 0x1ee9 0x1f2f 0x1fb6 0x2010 0x2073 0x20e1 0x2194 0x2254 0x2351 0x24cc>;
			battery2,battery_table1 = <0x00 0x65 0x1ed 0x2f3 0x3f8 0x4fe 0x709 0xb1f 0xeb2 0x13ce 0x18e9 0x1e05 0x2321 0x283c 0x2fe6 0x3501 0x3a1d 0x3f39 0x4454 0x4970 0x5119 0x58c3 0x6400 0x64e6>;
			battery2,battery_table2 = <0x1620 0x1113 0xf10 0xd0e 0xc0c 0xb0b 0xa0a 0xa0a>;
			battery2,alpha = <0xcc>;
			battery2,beta = <0x25>;
			battery2,rs = <0x5f>;
			battery2,rs_value = <0x50 0x10a 0x3800 0x48>;
			battery2,vit_period = <0x325a>;
			battery2,volt_cal = <0x8000>;
			battery2,mix_value = <3>;
			battery2,curr_offset = <0x00>;
			battery2,curr_slope = <0x8080>;
			battery2,topoff_soc = <7 300 100>;
			battery2,temp_std = <25>;
			battery2,temp_offset = <0 11 1 0 8 (-1)>;
			battery2,temp_cal = <0 6 1 11 (-1) 0 6 1 9 1>;
			battery2,ext_temp_cal = <0 2 1 2 1 1 2 3 2 3>;
			battery2,tempoff = <3400 100>;
			battery2,fcm_offset = <0x48>;
			battery2,thermal_table = <0x9d45 0x9cf7 0x9ca8 0x9c5a 0x9c0c 0x9bbe 0x9b70 0x9b21 0x9ad2 0x9a83 0x9a33 0x99e3 0x9992 0x9940 0x98ef 0x989d 0x984b 0x97f8 0x97a5 0x9752
				0x96fe 0x96aa 0x9656 0x9601 0x95ac 0x9556 0x9500 0x94aa 0x9454 0x93fd 0x93a6 0x934f 0x92f7 0x929f 0x9246 0x91ed 0x9194 0x913b 0x90e1 0x9087
				0x902d 0x8fd2 0x8f78 0x8f1c 0x8ec1 0x8e65 0x8e09 0x8dad 0x8d51 0x8cf4 0x8c97 0x8c3a 0x8bdd 0x8b7f 0x8b21 0x8ac3 0x8a65 0x8a06 0x89a8 0x8949
				0x88ea 0x888b 0x882c 0x87cc 0x876d 0x870d 0x86ad 0x864d 0x85ed 0x858d 0x852d 0x84d1 0x847c 0x842b 0x83db 0x8389 0x8332 0x82d3 0x8269 0x81f1
				0x8168 0x80aa 0x7fa2 0x7e62 0x7cfd 0x7b85 0x7a0e 0x78a9 0x7769 0x7662 0x75a5 0x751d 0x74a6 0x743d 0x73df 0x7388 0x7337 0x72e8 0x7297 0x7244
				0x71e9 0x718a 0x712b 0x70cd 0x706e 0x7010 0x6fb2 0x6f54 0x6ef6 0x6e98 0x6e3b 0x6dde 0x6d81 0x6d24 0x6cc7 0x6c6b 0x6c0e 0x6bb2 0x6b57 0x6afb
				0x6aa0 0x6a45 0x69ea 0x6990 0x6936 0x68dc 0x6882 0x6829 0x67cf 0x6777 0x671e 0x66c6 0x666e 0x6616 0x65bf 0x6567 0x6510 0x64ba 0x6464 0x640e
				0x63b8 0x6363 0x630e 0x62b9 0x6265 0x6211 0x61bd 0x6169 0x6116 0x60c3 0x6071 0x601f 0x5fcd 0x5f7b 0x5f2a 0x5ed9 0x5e89 0x5e39 0x5de9 0x5d99
				0x5d4a 0x5cfb 0x5cad 0x5c5f 0x5c11 0x5bc4 0x5b76 0x5b2a 0x5add 0x5a91 0x5a45 0x59f9 0x59ae 0x5963 0x5918 0x58ce 0x5884 0x583a 0x57f0 0x57a7
				0x575e 0x5715 0x56cd 0x5685 0x563d 0x55f6 0x55af 0x5568 0x5522 0x54db 0x5495 0x544f 0x540a 0x53c4 0x537f 0x533a 0x52f6 0x52b1 0x526d 0x5229
				0x51e5 0x51a1 0x515e 0x511a 0x50d7 0x5094 0x5052 0x500f 0x4fcc 0x4f8a 0x4f48 0x4f06 0x4ec4 0x4e83 0x4e41 0x4e00 0x4dbf 0x4d7e 0x4d3d 0x4cfc
				0x4cbb 0x4c7a 0x4c3a 0x4bf9 0x4bb8 0x4b78 0x4b38 0x4af7 0x4ab7 0x4a77 0x4a37 0x49f7 0x49b7 0x4977 0x4937 0x48f8 0x48b8 0x4879 0x4839 0x47f9
				0x47ba 0x477b 0x473b 0x46fc 0x46bd 0x467d 0x463e 0x45ff 0x45c0 0x4581 0x4542 0x4503 0x44c4 0x4485 0x4447 0x4408 0x43c9 0x438b 0x434c 0x430e
				0x42d0 0x4292 0x4254 0x4216 0x41d8 0x419a 0x415d 0x4120 0x40e2 0x40a6 0x4069 0x402d 0x3ff0 0x3fb4 0x3f79 0x3f3d 0x3f02 0x3ec6 0x3e8c 0x3e51
				0x3e17 0x3ddd 0x3da4 0x3d6a 0x3d31 0x3cf9 0x3cc0 0x3c88 0x3c50 0x3c18 0x3be1 0x3baa 0x3b73 0x3b3d 0x3b06 0x3ad1 0x3a9b 0x3a65 0x3a30 0x39fb
				0x39c6 0x3991 0x395d 0x3928 0x38f4 0x38c0 0x388c 0x3859 0x3826 0x37f3 0x37c0 0x378e 0x375b 0x3729 0x36f8 0x36c6 0x3695 0x3664 0x3634 0x3603
				0x35d3 0x35a3 0x3574 0x3544 0x3515 0x34e7 0x34b8 0x348a 0x345c 0x342e 0x3400 0x33d3 0x33a5 0x3378 0x334b 0x331f 0x32f2 0x32c6 0x329a 0x326e
				0x3242 0x3216 0x31ea 0x31bf 0x3193 0x3167 0x313c 0x3111 0x30e6 0x30bc 0x3092 0x3068 0x303f 0x3016 0x2fed 0x2fc5 0x2f9c 0x2f74 0x2f4c 0x2f25
				0x2efd 0x2ed6 0x2eaf 0x2e88 0x2e61 0x2e3b 0x2e14 0x2dee 0x2dc8 0x2da2 0x2d7c 0x2d56 0x2d30 0x2d0a 0x2ce5 0x2cbf 0x2c99 0x2c74 0x2c4f 0x2c2a
				0x2c06 0x2be2 0x2bbe 0x2b9a 0x2b77 0x2b54 0x2b31 0x2b0e 0x2aeb 0x2ac9 0x2aa6 0x2a83 0x2a61 0x2a3f 0x2a1c 0x29fa 0x29d9 0x29b7 0x2995 0x2974
				0x2953 0x2932 0x2912 0x28f2 0x28d2 0x28b2 0x2892 0x2872 0x2853 0x2833 0x2814 0x27f5 0x27d5 0x27b6 0x2796 0x2777 0x2758 0x2739 0x271a 0x26fc
				0x26de 0x26c0 0x26a3 0x2686 0x2669 0x264c 0x2630 0x2613 0x25f7 0x25da 0x25be 0x25a2 0x2585 0x2569 0x254c 0x2530 0x2514 0x24f8 0x24dc 0x24c0
				0x24a5 0x248a 0x246f 0x2454 0x2439 0x241f 0x2404 0x23ea 0x23d0 0x23b6 0x239c 0x2382 0x2369 0x234f 0x2336 0x231d 0x2304 0x22eb 0x22d2 0x22ba
				0x22a1 0x2289 0x2270 0x2258 0x2240 0x2228 0x2210 0x21f8 0x21e0 0x21c9 0x21b1 0x219a 0x2182 0x216b 0x2154 0x213c 0x2125 0x210f 0x20f8 0x20e1
				0x20cb 0x20b5 0x209f 0x2089 0x2073 0x205e 0x2048 0x2033 0x201d 0x2008 0x1ff3 0x1fde 0x1fc9 0x1fb4 0x1f9f 0x1f8a 0x1f75 0x1f61 0x1f4c 0x1f38
				0x1f23 0x1f0f 0x1efa 0x1ee6 0x1ed1 0x1ebd 0x1ea9 0x1e95 0x1e81 0x1e6d 0x1e59 0x1e45 0x1e32 0x1e1f 0x1e0b 0x1df8 0x1de5 0x1dd2 0x1dbf 0x1dad
				0x1d9a 0x1d88 0x1d75 0x1d63 0x1d51 0x1d3f 0x1d2e 0x1d1c 0x1d0a 0x1cf9 0x1ce7 0x1cd5 0x1cc4 0x1cb3 0x1ca1 0x1c90 0x1c7f 0x1c6e 0x1c5d 0x1c4c
				0x1c3b 0x1c2a 0x1c19 0x1c09 0x1bf8 0x1be7 0x1bd7 0x1bc6 0x1bb6 0x1ba5 0x1b95 0x1b85 0x1b75 0x1b65 0x1b55 0x1b45 0x1b35 0x1b25 0x1b16 0x1b06
				0x1af7 0x1ae8 0x1ad9 0x1ac9 0x1abb 0x1aac 0x1a9d 0x1a8e 0x1a7f 0x1a71 0x1a62 0x1a53 0x1a45 0x1a36 0x1a28 0x1a19 0x1a0b 0x19fc 0x19ee 0x19e0
				0x19d2 0x19c4 0x19b6 0x19a9 0x199b 0x198e 0x1980 0x1973 0x1965 0x1958 0x194b 0x193e 0x1931 0x1924 0x1917 0x190a 0x18fe 0x18f1 0x18e4 0x18d8
				0x18cb 0x18be 0x18b2 0x18a5 0x1899 0x188c 0x187f 0x1873 0x1867 0x185a 0x184e 0x1842 0x1836 0x1829 0x181d 0x1811 0x1805 0x17f9 0x17ed 0x17e2
				0x17d6 0x17ca 0x17bf 0x17b3 0x17a8 0x179d 0x1791 0x1786 0x177b 0x1770 0x1765 0x175a 0x174f 0x1744 0x173a 0x172f 0x1724 0x171a 0x170f 0x1705
				0x16fa 0x16f0 0x16e5 0x16db 0x16d0 0x16c6 0x16bc 0x16b1 0x16a7 0x169d 0x1693 0x1689 0x167f 0x1675 0x166b 0x1661 0x1658 0x164e 0x1644 0x163b
				0x1631 0x1627 0x161e 0x1614 0x160b 0x1601 0x15f8 0x15ef 0x15e5 0x15dc 0x15d3 0x15ca 0x15c1 0x15b8 0x15af 0x15a5 0x159d 0x1594 0x158b 0x1582
				0x1579 0x1570 0x1568 0x155f 0x1556 0x154e 0x1545 0x153d 0x1534 0x152c 0x1523 0x151a 0x1512 0x1509 0x1501 0x14f8 0x14f0 0x14e8 0x14df 0x14d7
				0x14cf 0x14c7 0x14bf 0x14b7 0x14af 0x14a8 0x14a0 0x1498 0x1490 0x1489 0x1481 0x1479 0x1472 0x146a 0x1462 0x145b 0x1453 0x144c 0x1444 0x143c
				0x1435 0x142e 0x1426 0x141f 0x1417 0x1410 0x1409 0x1402 0x13fa 0x13f3 0x13ec 0x13e5 0x13de 0x13d7 0x13d0 0x13c9 0x13c2 0x13bb 0x13b4 0x13ad
				0x13a6 0x139f 0x1399 0x1392 0x138b 0x1385 0x137e 0x1377 0x1371 0x136a 0x1364 0x135e 0x1357 0x1351 0x134a 0x1344 0x133e 0x1338 0x1331 0x132b
				0x1325 0x131f 0x1319 0x1313 0x130d 0x1307 0x1301 0x12fb 0x12f6 0x12f0 0x12ea 0x12e4 0x12de 0x12d9 0x12d3 0x12cd 0x12c7 0x12c2 0x12bc 0x12b7
				0x12b1 0x12ab 0x12a6 0x12a1 0x129b 0x1296 0x1290 0x128b 0x1286 0x1280 0x127b 0x1276 0x1270 0x126b 0x1265 0x1260 0x125a 0x1255 0x1250 0x124a
				0x1245 0x1240 0x123b 0x1235 0x1230 0x122b 0x1226 0x1221 0x121c 0x1217 0x1212 0x120d 0x1208 0x1203 0x11fe 0x11f9 0x11f4 0x11ef 0x11eb 0x11e6
				0x11e1 0x11dc 0x11d7 0x11d3 0x11ce 0x11c9 0x11c5 0x11c0 0x11bb 0x11b7 0x11b2 0x11ad 0x11a9 0x11a4 0x11a0 0x119b 0x1197 0x1192 0x118e 0x1189
				0x1185 0x1181 0x117c 0x1178 0x1174 0x116f 0x116b 0x1167 0x1162 0x115e 0x115a 0x1156 0x1152 0x114e 0x114a 0x1146 0x1142 0x113e 0x113a 0x1136
				0x1132 0x112e 0x112a 0x1126 0x1122 0x111e 0x111a 0x1117 0x1113 0x110f 0x110b 0x1107 0x1103 0x1100 0x10fc 0x10f8 0x10f5 0x10f1 0x10ed 0x10ea
				0x10e6 0x10e2 0x10df 0x10db 0x10d7 0x10d4 0x10d0 0x10cd 0x10c9 0x10c6 0x10c2 0x10bf 0x10bb 0x10b8 0x10b4 0x10b1 0x10ae 0x10aa 0x10a7 0x10a3
				0x10a0 0x109d 0x1099 0x1096 0x1092 0x108f 0x108b 0x1088 0x1085 0x1081 0x107e 0x107b 0x1077 0x1074 0x1071 0x106e 0x106b 0x1067 0x1064 0x1061
				0x105e 0x105b 0x1058 0x1055 0x1052 0x104f 0x104c 0x1049 0x1046 0x1043 0x1040 0x103d 0x103a 0x1037 0x1034 0x1031 0x102e 0x102b 0x1028 0x1025
				0x1022 0x101f 0x101c 0x1019 0x1017 0x1014 0x1011 0x100e 0x100c 0x1009 0x1006 0x1003 0x1000 0x0ffe 0x0ffb 0x0ff8 0x0ff5 0x0ff2 0x0fef 0x0fed
				0x0fea 0x0fe7 0x0fe5 0x0fe2 0x0fdf 0x0fdd 0x0fda 0x0fd8 0x0fd5 0x0fd3 0x0fd0 0x0fcd 0x0fcb 0x0fc8 0x0fc6 0x0fc3 0x0fc1 0x0fbe 0x0fbc 0x0fb9
				0x0fb7 0x0fb5 0x0fb2 0x0fb0 0x0fae 0x0fab 0x0fa9 0x0fa7 0x0fa5 0x0fa2 0x0fa0 0x0f9e 0x0f9c 0x0f99 0x0f97 0x0f95 0x0f93 0x0f91 0x0f8e 0x0f8c 0x0f8a>;
		};
	};

	/* CP pumper */
	sc8551-charger@66 {
		compatible = "sc,sc8551-standalone";
		reg = <0x66>;
		interrupt-parent = <&tlmm>;
		interrupts = <84 0>;
		pinctrl-names = "default";
		pinctrl-0 = <&sc8551_int_default>;
		intr-gpios = <&tlmm 84 0>;
		sc,sc8551,bat-therm-disable = <0>;
		sc,sc8551,bus-therm-disable = <0>;
		sc,sc8551,bat-ovp-threshold = <4525>;
		sc,sc8551,bat-ovp-alarm-threshold = <4400>;
		sc,sc8551,bat-ocp-threshold = <8000>;
		sc,sc8551,bat-ocp-alarm-threshold = <7500>;
		sc,sc8551,bus-ovp-threshold = <12000>;
		sc,sc8551,bus-ovp-alarm-threshold = <11000>;
		sc,sc8551,bus-ocp-threshold = <3750>;
		sc,sc8551,bus-ocp-alarm-threshold = <3500>;
		sc,sc8551,bat-ucp-alarm-threshold = <2000>;
		sc,sc8551,bat-therm-threshold = <21>;
		sc,sc8551,bus-therm-threshold = <21>;
		sc,sc8551,die-therm-threshold = <125>;
		sc,sc8551,ac-ovp-threshold = <17>;
		sc,sc8551,sense-resistor-mohm = <5>;
	};
};

&soc {
	rpm: rt-pd-manager {
		compatible = "richtek,rt-pd-manager";
	};

	xm_pd_adapter {
		compatible = "xiaomi,pd_adapter";
		adapter_name = "pd_adapter";
		alias_name = "xm_pd_adapter";
	};

	nopmi_chg: qcom,nopmi-chg {
		compatible = "qcom,nopmi-chg";
		status = "okay";
		qcom,fv-max-uv = <4400000>;
		enable_sw_jeita;
		jeita_temp_above_t4_cv = <4100>;
		jeita_temp_t3_to_t4_cv = <4100>;
		jeita_temp_t2_to_t3_cv = <4450>;
		jeita_temp_t1p5_to_t2_cv = <4450>;
		jeita_temp_t1_to_t1p5_cv = <4450>;
		jeita_temp_t0_to_t1_cv = <4450>;
		jeita_temp_tn1_to_t0_cv = <4450>;
		jeita_temp_below_t0_cv = <4450>;
		temp_t4_thres = <60>;
		temp_t4_thres_minus_x_degree = <58>;
		temp_t3_thres = <48>;
		temp_t3_thres_minus_x_degree = <46>;
		temp_t2_thres = <15>;
		temp_t2_thres_plus_x_degree = <17>;
		temp_t1p5_thres = <10>;
		temp_t1p5_thres_plus_x_degree = <11>;
		temp_t1_thres = <5>;
		temp_t1_thres_plus_x_degree = <6>;
		temp_t0_thres = <0>;
		temp_t0_thres_plus_x_degree = <1>;
		temp_tn1_thres = <0xfffffff6>;
		temp_tn1_thres_plus_x_degree = <0xfffffff7>;
		temp_neg_10_thres = <0xfffffff6>;
		temp_t3_to_t4_fcc = <2350>;
		temp_t2_to_t3_fcc = <5950>;
		temp_t1p5_to_t2_fcc = <3900>;
		temp_t1_to_t1p5_fcc = <2400>;
		temp_t0_to_t1_fcc = <950>;
		temp_tn1_to_t0_fcc = <490>;
		nopmi,thermal-mitigation = <5950000 5400000 5000000 4500000 4000000 3700000 3500000 3000000 2800000 2500000 2000000 1500000 1000000 800000 500000 300000>;
	};

	onewire_gpio: onewire_gpio {
		compatible = "xiaomi,onewire_gpio";
		label = "xm_onewire";
		xiaomi,onewire-gpios = <&tlmm 108 GPIO_ACTIVE_HIGH>;
		xiaomi,onewire-cfg-addr = <0x96c000 0x04>;
		pinctrl-names = "onewire_active", "onewire_sleep";
		pinctrl-0 = <&onewire_gpio_active>;
		pinctrl-1 = <&onewire_gpio_sleep>;
		status = "okay";
	};

	maxim_ds28e16: maxim_ds28e16 {
		compatible = "maxim,ds28e16";
		label = "max_ds28e16";
		xiaomi,onewire-bus = "xm_onewire";
		status = "okay";
	};

	cp_manager: cp_manager {
		compatible = "xiaomi,cp_manager";
		label = "cp_manager";
		fc2_disable_sw;
		bat_volt_lp_lmt = <4450>;
		bat_curr_lp_lmt = <5800>;
		bus_volt_lp_lmt = <12000>;
		bus_curr_lp_lmt = <2900>;
		fc2_taper_current = <2300>;
		fc2_steps = <1>;
		min_adapter_volt_required = <9000>;
		min_adapter_curr_required = <2000>;
		min_vbat_for_cp = <3500>;
		status = "okay";
	};
};

&usb0 {
	extcon = <&rpm &eud>;
};

&sdhc_2 {
	cd-gpios = <&tlmm 88 0>;
};

&reserved_memory {
	/* Pstore ramoops */
	ramoops_mem: ramoops@5d000000 {
		compatible = "ramoops";
		reg = <0x00 0x5d000000 0x00 0x800000>;
		record-size = <0x100000>;
		pmsg-size = <0x200000>;
		console-size = <0x200000>;
		ecc-size = <32>;
	};
};
